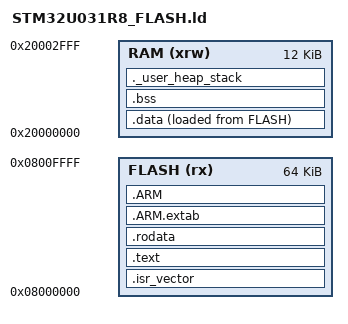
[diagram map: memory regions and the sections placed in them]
ENTRY(Reset_Handler)

_estack = ORIGIN(RAM) + LENGTH(RAM);

_Min_Heap_Size  = 0x200;
_Min_Stack_Size = 0x400;

MEMORY
{
  RAM   (xrw) : ORIGIN = 0x20000000, LENGTH = 12K
  FLASH (rx)  : ORIGIN = 0x08000000, LENGTH = 64K
}

SECTIONS
{
  .isr_vector :
  {
    KEEP(*(.isr_vector))
  } > FLASH

  .text :
  {
    *(.text)
    *(.text*)
    *(.glue_7)
    *(.glue_7t)
    *(.eh_frame)

    KEEP(*(.init))
    KEEP(*(.fini))

    _etext = .;
  } > FLASH

  .rodata :
  {
    *(.rodata)
    *(.rodata*)
  } > FLASH

  .ARM.extab :
  {
    *(.ARM.extab* .gnu.linkonce.armextab.*)
  } > FLASH

  .ARM :
  {
    __exidx_start = .;
    *(.ARM.exidx*)
    __exidx_end = .;
  } > FLASH

  _sidata = LOADADDR(.data);

  .data :
  {
    _sdata = .;
    *(.data)
    *(.data*)
    _edata = .;
  } > RAM AT> FLASH

  .bss :
  {
    _sbss = .;
    __bss_start__ = _sbss;
    *(.bss)
    *(.bss*)
    *(COMMON)
    _ebss = .;
    __bss_end__ = _ebss;
  } > RAM

  ._user_heap_stack :
  {
    . = ALIGN(8);
    PROVIDE(end = .);
    PROVIDE(_end = .);
    . = . + _Min_Heap_Size;
    . = . + _Min_Stack_Size;
    . = ALIGN(8);
  } > RAM
}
